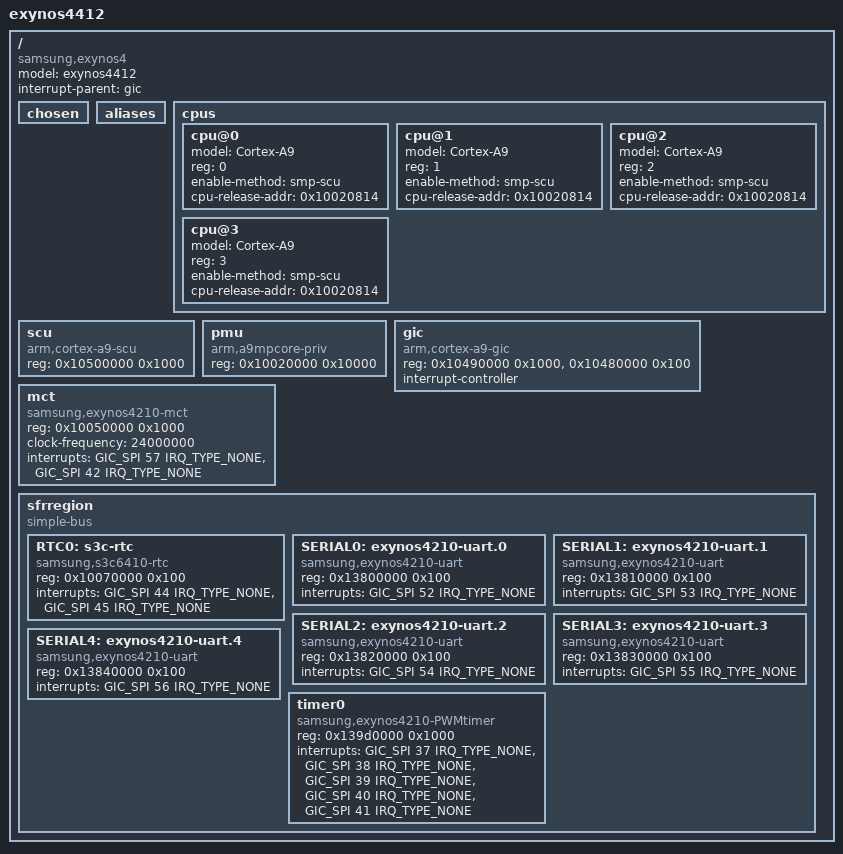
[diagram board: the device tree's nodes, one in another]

#include <dt-bindings/interrupt-controller/arm-gic.h>

/ {
	model = "exynos4412";
	compatible = "samsung,exynos4";
	interrupt-parent = <&gic>;
	#address-cells = <1>;
	#size-cells = <1>;

	chosen { };
	aliases { };

	cpus {
		#address-cells = <1>;
		#size-cells = <0>;

		cpu@0 {
			device_type = "cpu";
			model = "Cortex-A9";
			reg = <0>;
			enable-method = "smp-scu";
			cpu-release-addr = <0x10020814>;
		};

		cpu@1 {
			device_type = "cpu";
			model = "Cortex-A9";
			reg = <1>;
			enable-method = "smp-scu";
			cpu-release-addr = <0x10020814>;
		};

		cpu@2 {
			device_type = "cpu";
			model = "Cortex-A9";
			reg = <2>;
			enable-method = "smp-scu";
			cpu-release-addr = <0x10020814>;
		};

		cpu@3 {
			device_type = "cpu";
			model = "Cortex-A9";
			reg = <3>;
			enable-method = "smp-scu";
			cpu-release-addr = <0x10020814>;
		};
	};

	scu { /* Snoop Control Unit */
		compatible = "arm,cortex-a9-scu";
		reg = <0x10500000 0x1000>;
	};

	pmu { /* Performance Monitorig Unit */
		compatible = "arm,a9mpcore-priv";
		reg = <0x10020000 0x10000>;
	};

	gic: gic {
		compatible = "arm,cortex-a9-gic";
		reg = <0x10490000 0x1000>,
		      <0x10480000 0x100>;
		#interrupt-cells = <3>;
		interrupt-controller;
	};

	mct {
		compatible = "samsung,exynos4210-mct";
		reg = <0x10050000 0x1000>;
		clock-frequency = <24000000>;
		interrupts = <GIC_SPI 57 IRQ_TYPE_NONE>,
			     <GIC_SPI 42 IRQ_TYPE_NONE>;
	};

	sfrregion {
		#address-cells = <1>;
		#size-cells = <1>;
		compatible = "simple-bus";

		RTC0: s3c-rtc {
			compatible = "samsung,s3c6410-rtc";
			reg = <0x10070000 0x100>;
			interrupts = <GIC_SPI 44 IRQ_TYPE_NONE>,
				     <GIC_SPI 45 IRQ_TYPE_NONE>;
		};

		SERIAL0: exynos4210-uart.0 {
			compatible = "samsung,exynos4210-uart";
			reg = <0x13800000 0x100>;
			interrupts = <GIC_SPI 52 IRQ_TYPE_NONE>;
		};

		SERIAL1: exynos4210-uart.1 {
			compatible = "samsung,exynos4210-uart";
			reg = <0x13810000 0x100>;
			interrupts = <GIC_SPI 53 IRQ_TYPE_NONE>;
		};

		SERIAL2: exynos4210-uart.2 {
			compatible = "samsung,exynos4210-uart";
			reg = <0x13820000 0x100>;
			interrupts = <GIC_SPI 54 IRQ_TYPE_NONE>;
		};

		SERIAL3: exynos4210-uart.3 {
			compatible = "samsung,exynos4210-uart";
			reg = <0x13830000 0x100>;
			interrupts = <GIC_SPI 55 IRQ_TYPE_NONE>;
		};

		SERIAL4: exynos4210-uart.4 {
			compatible = "samsung,exynos4210-uart";
			reg = <0x13840000 0x100>;
			interrupts = <GIC_SPI 56 IRQ_TYPE_NONE>;
		};

		timer0 {
			compatible = "samsung,exynos4210-PWMtimer";
			reg = <0x139d0000 0x1000>;
			interrupts = <GIC_SPI 37 IRQ_TYPE_NONE>,
				     <GIC_SPI 38 IRQ_TYPE_NONE>,
				     <GIC_SPI 39 IRQ_TYPE_NONE>,
				     <GIC_SPI 40 IRQ_TYPE_NONE>,
				     <GIC_SPI 41 IRQ_TYPE_NONE>;
		};
	};
};
